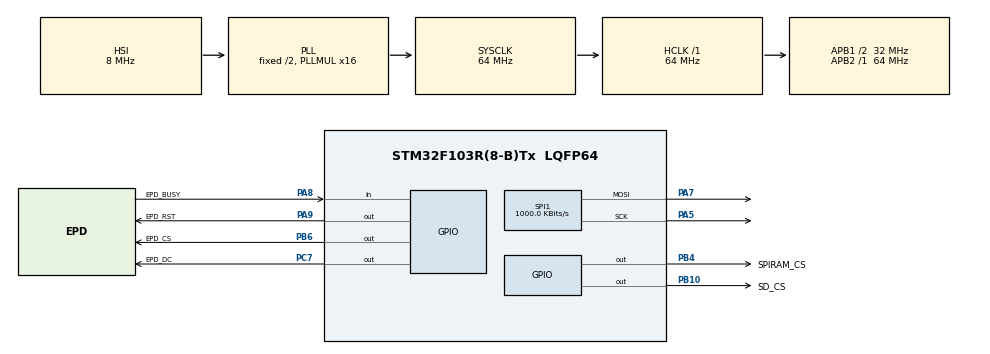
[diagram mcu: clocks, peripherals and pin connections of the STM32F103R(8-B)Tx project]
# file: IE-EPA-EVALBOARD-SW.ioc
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Mcu.Family=STM32F1
Mcu.Name=STM32F103R(8-B)Tx
Mcu.Package=LQFP64
NVIC.PriorityGroup=NVIC_PRIORITYGROUP_4
PA13.Mode=Serial_Wire
PA13.Signal=SYS_JTMS-SWDIO
PA14.Mode=Serial_Wire
PA14.Signal=SYS_JTCK-SWCLK
PA5.Mode=TX_Only_Simplex_Unidirect_Master
PA5.Signal=SPI1_SCK
PA7.Mode=TX_Only_Simplex_Unidirect_Master
PA7.Signal=SPI1_MOSI
PA8.GPIO_Label=EPD_BUSY
PA8.GPIO_PuPd=GPIO_NOPULL
PA8.Signal=GPIO_Input
PA9.GPIO_Label=EPD_RST
PA9.GPIO_ModeDefaultOutputPP=GPIO_MODE_OUTPUT_PP
PA9.GPIO_PuPd=GPIO_PULLUP
PA9.GPIO_Speed=GPIO_SPEED_FREQ_LOW
PA9.PinState=GPIO_PIN_RESET
PA9.Signal=GPIO_Output
PB10.GPIO_Label=SD_CS
PB10.GPIO_ModeDefaultOutputPP=GPIO_MODE_OUTPUT_PP
PB10.GPIO_PuPd=GPIO_PULLUP
PB10.GPIO_Speed=GPIO_SPEED_FREQ_HIGH
PB10.PinState=GPIO_PIN_SET
PB10.Signal=GPIO_Output
PB4.GPIO_Label=SPIRAM_CS
PB4.GPIO_ModeDefaultOutputPP=GPIO_MODE_OUTPUT_PP
PB4.GPIO_PuPd=GPIO_PULLUP
PB4.GPIO_Speed=GPIO_SPEED_FREQ_HIGH
PB4.PinState=GPIO_PIN_SET
PB4.Signal=GPIO_Output
PB6.GPIO_Label=EPD_CS
PB6.GPIO_ModeDefaultOutputPP=GPIO_MODE_OUTPUT_PP
PB6.GPIO_PuPd=GPIO_PULLUP
PB6.GPIO_Speed=GPIO_SPEED_FREQ_HIGH
PB6.PinState=GPIO_PIN_SET
PB6.Signal=GPIO_Output
PC7.GPIO_Label=EPD_DC
PC7.GPIO_ModeDefaultOutputPP=GPIO_MODE_OUTPUT_PP
PC7.GPIO_PuPd=GPIO_PULLUP
PC7.GPIO_Speed=GPIO_SPEED_FREQ_HIGH
PC7.PinState=GPIO_PIN_RESET
PC7.Signal=GPIO_Output
ProjectManager.HeapSize=0x400
ProjectManager.StackSize=0x800
ProjectManager.TargetToolchain=STM32CubeIDE
RCC.AHBFreq_Value=64000000
RCC.APB1CLKDivider=RCC_HCLK_DIV2
RCC.APB1Freq_Value=32000000
RCC.APB1TimFreq_Value=64000000
RCC.APB2Freq_Value=64000000
RCC.APB2TimFreq_Value=64000000
RCC.HCLKFreq_Value=64000000
RCC.HSEDivPLL=RCC_HSE_PREDIV_DIV2
RCC.PLLMUL=RCC_PLL_MUL16
RCC.SYSCLKFreq_VALUE=64000000
RCC.SYSCLKSource=RCC_SYSCLKSOURCE_PLLCLK
RCC.USBFreq_Value=64000000
SPI1.BaudRatePrescaler=SPI_BAUDRATEPRESCALER_64
SPI1.CalculateBaudRate=1000.0 KBits/s
SPI1.Direction=SPI_DIRECTION_2LINES
SPI1.Mode=SPI_MODE_MASTER
SPI1.VirtualType=VM_MASTER
board=epd1in54

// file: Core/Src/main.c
/* USER CODE BEGIN Header */
/**
  ******************************************************************************
  * @file           : main.c
  * @brief          : Main program body
  ******************************************************************************
  * @attention
  *
  * Copyright (c) 2025 STMicroelectronics.
  * All rights reserved.
  *
  * This software is licensed under terms that can be found in the LICENSE file
  * in the root directory of this software component.
  * If no LICENSE file comes with this software, it is provided AS-IS.
  *
  ******************************************************************************
  */
/* USER CODE END Header */
#include "main.h"
#include "spi.h"
#include "gpio.h"

/* USER CODE BEGIN Includes */
#include "demo.h"
/* USER CODE END Includes */

void SystemClock_Config(void);

int main(void)
{

  /* MCU Configuration--------------------------------------------------------*/

  /* Reset of all peripherals, Initializes the Flash interface and the Systick. */
  HAL_Init();

  /* Configure the system clock */
  SystemClock_Config();

  /* Initialize all configured peripherals */
  MX_GPIO_Init();
  MX_SPI1_Init();

//////////////////////// FUNKCJA TESTOWA/////////////////////////////////
  //EPD_Init(128, 296);
  //HAL_Delay(300);

 /* static uint8_t pattern[128/8 * 296];
  static uint8_t red[128/8 * 296];

  // Wyczyść oba bufory
  memset(pattern, 0xFF, sizeof(pattern)); // całość biała (bo bit 1 = biały)
  memset(red, 0x00, sizeof(red));         // brak czerwieni

  int width_bytes = 128 / 8;

  // 1. Prostokąt 1: biały (128x100)
  // To już jest cały ekran ustawiony na biały w pattern (0xFF),
  // więc nic nie trzeba zmieniać w pierwszych 100 liniach.

  // 2. Prostokąt 2: czarny (128x100) od wiersza 100 do 199
  // czarny = bit 0, czyli ustawiamy bity pattern na 0 w tych liniach
  for (int y = 100; y < 200; y++) {
      int offset = y * width_bytes;
      memset(&pattern[offset], 0x00, width_bytes); // czarne pixele
  }

  // 3. Prostokąt 3: czerwony (128x96) od wiersza 200 do 295
  // czerwony = ustawiamy red = 0xFF, pattern może być 0x00 lub 0xFF
  // żeby mieć wyraźny czerwony, ustawimy pattern na 0 (czarny) i red na 1
  for (int y = 200; y < 296; y++) {
      int offset = y * width_bytes;
      memset(&pattern[offset], 0x00, width_bytes);  // czarne tło
      memset(&red[offset], 0xFF, width_bytes);      // czerwone pixele
  }

  EPD_Display(pattern, red, 128, 296);
  HAL_Delay(3000);

*/
  //////////////////////// FUNKCJA TESTOWA/////////////////////////////////
  //while (HAL_GPIO_ReadPin(GPIOA, GPIO_PIN_12) == GPIO_PIN_SET); // próbowałem ogarnąć przycisk, ale coś nie chwyta - podpięty jest miedzy GND a PA12
  // jak ktoś chce się pobawić to reszta kodu jest w gpio.c i na dole maina, oznaczone "SWITCH"
  demo_V1();     //Wyświetla testowe 3 prostokąty W B R
  //demo_V2();     //Wyświetla image  gImage_logo248x46
  //demo_V3();       // Wyświetla string1 i string2

  /* USER CODE END 2 */

  /* Infinite loop */
  while (1)
  {

  }
}

void SystemClock_Config(void)
{
  RCC_OscInitTypeDef RCC_OscInitStruct = {0};
  RCC_ClkInitTypeDef RCC_ClkInitStruct = {0};

  /** Initializes the RCC Oscillators according to the specified parameters
  * in the RCC_OscInitTypeDef structure.
  */
  RCC_OscInitStruct.OscillatorType = RCC_OSCILLATORTYPE_HSI;
  RCC_OscInitStruct.HSIState = RCC_HSI_ON;
  RCC_OscInitStruct.HSICalibrationValue = RCC_HSICALIBRATION_DEFAULT;
  RCC_OscInitStruct.PLL.PLLState = RCC_PLL_ON;
  RCC_OscInitStruct.PLL.PLLSource = RCC_PLLSOURCE_HSI_DIV2;
  RCC_OscInitStruct.PLL.PLLMUL = RCC_PLL_MUL16;
  if (HAL_RCC_OscConfig(&RCC_OscInitStruct) != HAL_OK)
  {
    Error_Handler();
  }

  /** Initializes the CPU, AHB and APB buses clocks
  */
  RCC_ClkInitStruct.ClockType = RCC_CLOCKTYPE_HCLK|RCC_CLOCKTYPE_SYSCLK
                              |RCC_CLOCKTYPE_PCLK1|RCC_CLOCKTYPE_PCLK2;
  RCC_ClkInitStruct.SYSCLKSource = RCC_SYSCLKSOURCE_PLLCLK;
  RCC_ClkInitStruct.AHBCLKDivider = RCC_SYSCLK_DIV1;
  RCC_ClkInitStruct.APB1CLKDivider = RCC_HCLK_DIV2;
  RCC_ClkInitStruct.APB2CLKDivider = RCC_HCLK_DIV1;

  if (HAL_RCC_ClockConfig(&RCC_ClkInitStruct, FLASH_LATENCY_2) != HAL_OK)
  {
    Error_Handler();
  }
}

/* USER CODE BEGIN 4 */

/*SWITCH
void HAL_GPIO_EXTI_Callback(uint16_t GPIO_Pin) {
    if (GPIO_Pin == GPIO_PIN_12) {
        // Wybudzenie lub jakaś akcja po przerwaniu
    }
}*/

/* USER CODE END 4 */

void Error_Handler(void)
{
  __disable_irq();
  while (1)
  {
  }
}
